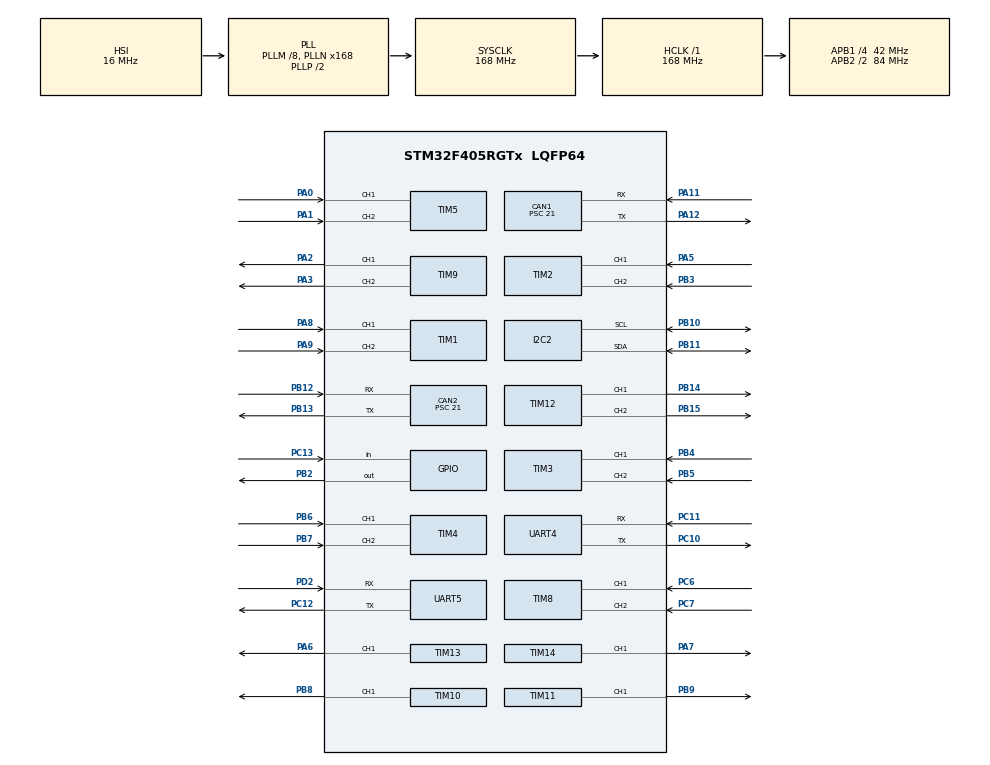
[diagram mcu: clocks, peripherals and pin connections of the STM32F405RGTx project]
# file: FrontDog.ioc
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CAN1.BS1=CAN_BS1_2TQ
CAN1.CalculateBaudRate=500000
CAN1.CalculateTimeBit=2000
CAN1.CalculateTimeQuantum=500.0
CAN1.NART=ENABLE
CAN1.Prescaler=21
CAN1.TXFP=ENABLE
CAN2.BS1=CAN_BS1_2TQ
CAN2.CalculateBaudRate=500000
CAN2.CalculateTimeBit=2000
CAN2.CalculateTimeQuantum=500.0
CAN2.NART=ENABLE
CAN2.Prescaler=21
CAN2.TXFP=ENABLE
Dma.Request0=UART4_RX
Dma.Request1=UART4_TX
Dma.Request2=UART5_RX
Dma.Request3=UART5_TX
Dma.UART4_RX.0.Direction=DMA_PERIPH_TO_MEMORY
Dma.UART4_RX.0.FIFOMode=DMA_FIFOMODE_DISABLE
Dma.UART4_RX.0.Instance=DMA1_Stream2
Dma.UART4_RX.0.MemDataAlignment=DMA_MDATAALIGN_BYTE
Dma.UART4_RX.0.MemInc=DMA_MINC_ENABLE
Dma.UART4_RX.0.Mode=DMA_NORMAL
Dma.UART4_RX.0.PeriphDataAlignment=DMA_PDATAALIGN_BYTE
Dma.UART4_RX.0.PeriphInc=DMA_PINC_DISABLE
Dma.UART4_RX.0.Priority=DMA_PRIORITY_LOW
Dma.UART4_TX.1.Direction=DMA_MEMORY_TO_PERIPH
Dma.UART4_TX.1.FIFOMode=DMA_FIFOMODE_DISABLE
Dma.UART4_TX.1.Instance=DMA1_Stream4
Dma.UART4_TX.1.MemDataAlignment=DMA_MDATAALIGN_BYTE
Dma.UART4_TX.1.MemInc=DMA_MINC_ENABLE
Dma.UART4_TX.1.Mode=DMA_NORMAL
Dma.UART4_TX.1.PeriphDataAlignment=DMA_PDATAALIGN_BYTE
Dma.UART4_TX.1.PeriphInc=DMA_PINC_DISABLE
Dma.UART4_TX.1.Priority=DMA_PRIORITY_LOW
Dma.UART5_RX.2.Direction=DMA_PERIPH_TO_MEMORY
Dma.UART5_RX.2.FIFOMode=DMA_FIFOMODE_DISABLE
Dma.UART5_RX.2.Instance=DMA1_Stream0
Dma.UART5_RX.2.MemDataAlignment=DMA_MDATAALIGN_BYTE
Dma.UART5_RX.2.MemInc=DMA_MINC_ENABLE
Dma.UART5_RX.2.Mode=DMA_NORMAL
Dma.UART5_RX.2.PeriphDataAlignment=DMA_PDATAALIGN_BYTE
Dma.UART5_RX.2.PeriphInc=DMA_PINC_DISABLE
Dma.UART5_RX.2.Priority=DMA_PRIORITY_LOW
Dma.UART5_TX.3.Direction=DMA_MEMORY_TO_PERIPH
Dma.UART5_TX.3.FIFOMode=DMA_FIFOMODE_DISABLE
Dma.UART5_TX.3.Instance=DMA1_Stream7
Dma.UART5_TX.3.MemDataAlignment=DMA_MDATAALIGN_BYTE
Dma.UART5_TX.3.MemInc=DMA_MINC_ENABLE
Dma.UART5_TX.3.Mode=DMA_NORMAL
Dma.UART5_TX.3.PeriphDataAlignment=DMA_PDATAALIGN_BYTE
Dma.UART5_TX.3.PeriphInc=DMA_PINC_DISABLE
Dma.UART5_TX.3.Priority=DMA_PRIORITY_LOW
FREERTOS.BinarySemaphores01=CAN_TX_BS,Static,CAN_TX_BSControlBlock,Available;UART_RX_BS,Static,UART_RX_BSControlBlock,Available
FREERTOS.CountingSemaphores01=UART_TX_CS,16,Static,UART_TX_CSControlBlock,0
FREERTOS.Queues01=UART_RX_Q,16,uint8_t,0,Static,UART_RX_QBuffer,UART_RX_QControlBlock;KEY_CMD_Q,16,App_Key_EventPacket_t,0,Static,KEY_CMD_QBuffer,KEY_CMD_QControlBlock;CAN_RXF0_Q,16,BSP_CAN_Packet_t,0,Static,CAN_RXF0_QBuffer,CAN_RXF0_QControlBlock;CAN_RXF1_Q,16,BSP_CAN_Packet_t,0,Static,CAN_RXF1_QBuffer,CAN_RXF1_QControlBlock;UART_TX_Q,16,APP_TxFrame_t,0,Static,UART_TX_QBuffer,UART_TX_QControlBlock
FREERTOS.Tasks01=KEY_Debounce_T,52,128,Task_KEY_Debounce,As weak,NULL,Static,KEY_Debounce_TBuffer,KEY_Debounce_TControlBlock;KEY_CMD_T,45,256,TASK_KEY_CMD,As weak,NULL,Static,KEY_CMD_TBuffer,KEY_CMD_TControlBlock;UART_RX_T,51,256,Task_UART_RX,As weak,NULL,Static,UART_RX_TBuffer,UART_RX_TControlBlock;UART_TX_T,38,128,Task_UART_TX,As weak,NULL,Static,UART_TX_TBuffer,UART_TX_TControlBlock;SERVO_T,46,64,Task_SERVO_T,As weak,NULL,Static,SERVO_TBuffer,SERVO_TControlBlock;OLED_T,14,128,Task_OLED,As weak,NULL,Static,OLED_TBuffer,OLED_TControlBlock;CAN_RXF0_T,54,256,Task_CAN_RXF0,As weak,NULL,Static,CAN_RXF0_TBuffer,CAN_RXF0_TControlBlock;CAN_RXF1_T,53,256,Task_CAN_RXF1,As weak,NULL,Static,CAN_RXF1_TBuffer,CAN_RXF1_TControlBlock;CAN_TX_T,37,64,Task_CAN_TX,As weak,NULL,Static,CAN_TX_TBuffer,CAN_TX_TControlBlock;UART_RX_CMD,50,128,Task_UART_RX_CMD,As weak,NULL,Static,UART_RX_CMDBuffer,UART_RX_CMDControlBlock
FREERTOS.configMINIMAL_STACK_SIZE=64
FREERTOS.configTOTAL_HEAP_SIZE=256
Mcu.Family=STM32F4
Mcu.Name=STM32F405RGTx
Mcu.Package=LQFP64
NVIC.CAN1_RX0_IRQn=true\:5\:0\:false\:false\:true\:true\:true\:true\:true
NVIC.CAN1_RX1_IRQn=true\:5\:0\:false\:false\:true\:true\:true\:true\:true
NVIC.CAN2_RX0_IRQn=true\:5\:0\:false\:false\:true\:true\:true\:true\:true
NVIC.CAN2_RX1_IRQn=true\:5\:0\:false\:false\:true\:true\:true\:true\:true
NVIC.DMA1_Stream0_IRQn=true\:5\:0\:false\:false\:true\:true\:false\:true\:true
NVIC.DMA1_Stream2_IRQn=true\:5\:0\:false\:false\:true\:true\:false\:true\:true
NVIC.DMA1_Stream4_IRQn=true\:5\:0\:false\:false\:true\:true\:false\:true\:true
NVIC.DMA1_Stream7_IRQn=true\:5\:0\:false\:false\:true\:true\:false\:true\:true
NVIC.PriorityGroup=NVIC_PRIORITYGROUP_4
NVIC.TIM6_DAC_IRQn=true\:15\:0\:false\:false\:true\:false\:false\:true\:true
NVIC.TimeBase=TIM6_DAC_IRQn
NVIC.TimeBaseIP=TIM6
NVIC.UART4_IRQn=true\:5\:0\:false\:false\:true\:true\:true\:true\:true
NVIC.UART5_IRQn=true\:5\:0\:false\:false\:true\:true\:true\:true\:true
PA0-WKUP.Signal=S_TIM5_CH1
PA1.Signal=S_TIM5_CH2
PA11.Mode=CAN_Activate
PA11.Signal=CAN1_RX
PA12.Mode=CAN_Activate
PA12.Signal=CAN1_TX
PA13.Mode=Serial_Wire
PA13.Signal=SYS_JTMS-SWDIO
PA14.Mode=Serial_Wire
PA14.Signal=SYS_JTCK-SWCLK
PA2.Signal=S_TIM9_CH1
PA3.Signal=S_TIM9_CH2
PA5.Signal=S_TIM2_CH1_ETR
PA6.Signal=S_TIM13_CH1
PA7.Signal=S_TIM14_CH1
PA8.Signal=S_TIM1_CH1
PA9.Signal=S_TIM1_CH2
PB10.Mode=I2C
PB10.Signal=I2C2_SCL
PB11.Mode=I2C
PB11.Signal=I2C2_SDA
PB12.Mode=CAN_Activate
PB12.Signal=CAN2_RX
PB13.Mode=CAN_Activate
PB13.Signal=CAN2_TX
PB14.Signal=S_TIM12_CH1
PB15.Signal=S_TIM12_CH2
PB2.GPIO_PuPd=GPIO_PULLDOWN
PB2.Signal=GPIO_Output
PB3.Signal=S_TIM2_CH2
PB4.Signal=S_TIM3_CH1
PB5.Signal=S_TIM3_CH2
PB6.Signal=S_TIM4_CH1
PB7.Signal=S_TIM4_CH2
PB8.Signal=S_TIM10_CH1
PB9.Signal=S_TIM11_CH1
PC10.Mode=Asynchronous
PC10.Signal=UART4_TX
PC11.Mode=Asynchronous
PC11.Signal=UART4_RX
PC12.Mode=Asynchronous
PC12.Signal=UART5_TX
PC13-ANTI_TAMP.GPIO_PuPd=GPIO_PULLDOWN
PC13-ANTI_TAMP.Signal=GPIO_Input
PC6.Signal=S_TIM8_CH1
PC7.Signal=S_TIM8_CH2
PD2.Mode=Asynchronous
PD2.Signal=UART5_RX
PH0-OSC_IN.Mode=HSE-External-Oscillator
PH0-OSC_IN.Signal=RCC_OSC_IN
PH1-OSC_OUT.Mode=HSE-External-Oscillator
PH1-OSC_OUT.Signal=RCC_OSC_OUT
ProjectManager.HeapSize=0x200
ProjectManager.StackSize=0x400
ProjectManager.TargetToolchain=CMake
RCC.48MHZClocksFreq_Value=84000000
RCC.AHBFreq_Value=168000000
RCC.APB1CLKDivider=RCC_HCLK_DIV4
RCC.APB1Freq_Value=42000000
RCC.APB1TimFreq_Value=84000000
RCC.APB2CLKDivider=RCC_HCLK_DIV2
RCC.APB2Freq_Value=84000000
RCC.APB2TimFreq_Value=168000000
RCC.CortexFreq_Value=168000000
RCC.HCLKFreq_Value=168000000
RCC.HSE_VALUE=8000000
RCC.HSI_VALUE=16000000
RCC.LSE_VALUE=32768
RCC.PLLM=8
RCC.PLLN=168
RCC.SYSCLKFreq_VALUE=168000000
RCC.SYSCLKSource=RCC_SYSCLKSOURCE_PLLCLK
RCC.VCOOutputFreq_Value=336000000
SH.S_TIM10_CH1.0=TIM10_CH1,PWM Generation1 CH1
SH.S_TIM11_CH1.0=TIM11_CH1,PWM Generation1 CH1
SH.S_TIM12_CH1.0=TIM12_CH1,PWM Generation1 CH1
SH.S_TIM12_CH2.0=TIM12_CH2,PWM Generation2 CH2
SH.S_TIM13_CH1.0=TIM13_CH1,PWM Generation1 CH1
SH.S_TIM14_CH1.0=TIM14_CH1,PWM Generation1 CH1
SH.S_TIM1_CH1.0=TIM1_CH1,Encoder_Interface
SH.S_TIM1_CH2.0=TIM1_CH2,Encoder_Interface
SH.S_TIM2_CH1_ETR.0=TIM2_CH1,Encoder_Interface
SH.S_TIM2_CH2.0=TIM2_CH2,Encoder_Interface
SH.S_TIM3_CH1.0=TIM3_CH1,Encoder_Interface
SH.S_TIM3_CH2.0=TIM3_CH2,Encoder_Interface
SH.S_TIM4_CH1.0=TIM4_CH1,Encoder_Interface
SH.S_TIM4_CH2.0=TIM4_CH2,Encoder_Interface
SH.S_TIM5_CH1.0=TIM5_CH1,Encoder_Interface
SH.S_TIM5_CH2.0=TIM5_CH2,Encoder_Interface
SH.S_TIM8_CH1.0=TIM8_CH1,Encoder_Interface
SH.S_TIM8_CH2.0=TIM8_CH2,Encoder_Interface
SH.S_TIM9_CH1.0=TIM9_CH1,PWM Generation1 CH1
SH.S_TIM9_CH2.0=TIM9_CH2,PWM Generation2 CH2
TIM10.Channel=TIM_CHANNEL_1
TIM11.Channel=TIM_CHANNEL_1
TIM12.Channel-PWM\ Generation1\ CH1=TIM_CHANNEL_1
TIM12.Channel-PWM\ Generation2\ CH2=TIM_CHANNEL_2
TIM13.Channel=TIM_CHANNEL_1
TIM14.Channel=TIM_CHANNEL_1
TIM9.Channel-PWM\ Generation1\ CH1=TIM_CHANNEL_1
TIM9.Channel-PWM\ Generation2\ CH2=TIM_CHANNEL_2
UART4.VirtualMode=Asynchronous
UART5.VirtualMode=Asynchronous
VP_FREERTOS_VS_CMSIS_V2.Mode=CMSIS_V2
VP_SYS_VS_tim6.Mode=TIM6
VP_TIM10_VS_ClockSourceINT.Mode=Enable_Timer
VP_TIM11_VS_ClockSourceINT.Mode=Enable_Timer
VP_TIM12_VS_ClockSourceINT.Mode=Internal
VP_TIM13_VS_ClockSourceINT.Mode=Enable_Timer
VP_TIM14_VS_ClockSourceINT.Mode=Enable_Timer
VP_TIM9_VS_ClockSourceINT.Mode=Internal
board=custom

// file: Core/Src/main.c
/* USER CODE BEGIN Header */
/**
  ******************************************************************************
  * @file           : main.c
  * @brief          : Main program body
  ******************************************************************************
  * @attention
  *
  * Copyright (c) 2026 STMicroelectronics.
  * All rights reserved.
  *
  * This software is licensed under terms that can be found in the LICENSE file
  * in the root directory of this software component.
  * If no LICENSE file comes with this software, it is provided AS-IS.
  *
  ******************************************************************************
  */
/* USER CODE END Header */
#include "main.h"
#include "cmsis_os.h"
#include "can.h"
#include "dma.h"
#include "i2c.h"
#include "tim.h"
#include "usart.h"
#include "gpio.h"

void SystemClock_Config(void);
void MX_FREERTOS_Init(void);

int main(void)
{

  /* MCU Configuration--------------------------------------------------------*/

  /* Reset of all peripherals, Initializes the Flash interface and the Systick. */
  HAL_Init();

  /* Configure the system clock */
  SystemClock_Config();

  /* Initialize all configured peripherals */
  MX_GPIO_Init();
  MX_DMA_Init();
  MX_CAN1_Init();
  MX_CAN2_Init();
  MX_I2C2_Init();
  MX_TIM1_Init();
  MX_TIM2_Init();
  MX_TIM3_Init();
  MX_TIM4_Init();
  MX_TIM5_Init();
  MX_TIM8_Init();
  MX_TIM9_Init();
  MX_TIM10_Init();
  MX_TIM11_Init();
  MX_TIM12_Init();
  MX_TIM13_Init();
  MX_TIM14_Init();
  MX_UART4_Init();
  MX_UART5_Init();

  /* Init scheduler */
  osKernelInitialize();  /* Call init function for freertos objects (in cmsis_os2.c) */
  MX_FREERTOS_Init();

  /* Start scheduler */
  osKernelStart();

  /* We should never get here as control is now taken by the scheduler */

  /* Infinite loop */
  while (1)
  {

  }
}

void SystemClock_Config(void)
{
  RCC_OscInitTypeDef RCC_OscInitStruct = {0};
  RCC_ClkInitTypeDef RCC_ClkInitStruct = {0};

  /** Configure the main internal regulator output voltage
  */
  __HAL_RCC_PWR_CLK_ENABLE();
  __HAL_PWR_VOLTAGESCALING_CONFIG(PWR_REGULATOR_VOLTAGE_SCALE1);

  /** Initializes the RCC Oscillators according to the specified parameters
  * in the RCC_OscInitTypeDef structure.
  */
  RCC_OscInitStruct.OscillatorType = RCC_OSCILLATORTYPE_HSI;
  RCC_OscInitStruct.HSIState = RCC_HSI_ON;
  RCC_OscInitStruct.HSICalibrationValue = RCC_HSICALIBRATION_DEFAULT;
  RCC_OscInitStruct.PLL.PLLState = RCC_PLL_ON;
  RCC_OscInitStruct.PLL.PLLSource = RCC_PLLSOURCE_HSI;
  RCC_OscInitStruct.PLL.PLLM = 8;
  RCC_OscInitStruct.PLL.PLLN = 168;
  RCC_OscInitStruct.PLL.PLLP = RCC_PLLP_DIV2;
  RCC_OscInitStruct.PLL.PLLQ = 4;
  if (HAL_RCC_OscConfig(&RCC_OscInitStruct) != HAL_OK)
  {
    Error_Handler();
  }

  /** Initializes the CPU, AHB and APB buses clocks
  */
  RCC_ClkInitStruct.ClockType = RCC_CLOCKTYPE_HCLK|RCC_CLOCKTYPE_SYSCLK
                              |RCC_CLOCKTYPE_PCLK1|RCC_CLOCKTYPE_PCLK2;
  RCC_ClkInitStruct.SYSCLKSource = RCC_SYSCLKSOURCE_PLLCLK;
  RCC_ClkInitStruct.AHBCLKDivider = RCC_SYSCLK_DIV1;
  RCC_ClkInitStruct.APB1CLKDivider = RCC_HCLK_DIV4;
  RCC_ClkInitStruct.APB2CLKDivider = RCC_HCLK_DIV2;

  if (HAL_RCC_ClockConfig(&RCC_ClkInitStruct, FLASH_LATENCY_5) != HAL_OK)
  {
    Error_Handler();
  }
}

void HAL_TIM_PeriodElapsedCallback(TIM_HandleTypeDef *htim)
{
  if (htim->Instance == TIM6)
  {
    HAL_IncTick();
  }
}

void Error_Handler(void)
{
  __disable_irq();
  while (1)
  {
  }
}

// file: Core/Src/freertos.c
/* USER CODE BEGIN Header */
/**
  ******************************************************************************
  * File Name          : freertos.c
  * Description        : Code for freertos applications
  ******************************************************************************
  * @attention
  *
  * Copyright (c) 2026 STMicroelectronics.
  * All rights reserved.
  *
  * This software is licensed under terms that can be found in the LICENSE file
  * in the root directory of this software component.
  * If no LICENSE file comes with this software, it is provided AS-IS.
  *
  ******************************************************************************
  */
/* USER CODE END Header */

#include "FreeRTOS.h"
#include "task.h"
#include "main.h"
#include "cmsis_os.h"

/* USER CODE BEGIN Includes */
#include "app_key.h"
#include "bsp_can.h"
#include "app_uart.h"
/* USER CODE END Includes */

typedef StaticTask_t osStaticThreadDef_t;
typedef StaticQueue_t osStaticMessageQDef_t;
typedef StaticSemaphore_t osStaticSemaphoreDef_t;

/* Definitions for KEY_Debounce_T */
osThreadId_t KEY_Debounce_THandle;
uint32_t KEY_Debounce_TBuffer[ 128 ];
osStaticThreadDef_t KEY_Debounce_TControlBlock;
const osThreadAttr_t KEY_Debounce_T_attributes = {
  .name = "KEY_Debounce_T",
  .cb_mem = &KEY_Debounce_TControlBlock,
  .cb_size = sizeof(KEY_Debounce_TControlBlock),
  .stack_mem = &KEY_Debounce_TBuffer[0],
  .stack_size = sizeof(KEY_Debounce_TBuffer),
  .priority = (osPriority_t) osPriorityRealtime4,
};
/* Definitions for KEY_CMD_T */
osThreadId_t KEY_CMD_THandle;
uint32_t KEY_CMD_TBuffer[ 256 ];
osStaticThreadDef_t KEY_CMD_TControlBlock;
const osThreadAttr_t KEY_CMD_T_attributes = {
  .name = "KEY_CMD_T",
  .cb_mem = &KEY_CMD_TControlBlock,
  .cb_size = sizeof(KEY_CMD_TControlBlock),
  .stack_mem = &KEY_CMD_TBuffer[0],
  .stack_size = sizeof(KEY_CMD_TBuffer),
  .priority = (osPriority_t) osPriorityHigh5,
};
/* Definitions for UART_RX_T */
osThreadId_t UART_RX_THandle;
uint32_t UART_RX_TBuffer[ 256 ];
osStaticThreadDef_t UART_RX_TControlBlock;
const osThreadAttr_t UART_RX_T_attributes = {
  .name = "UART_RX_T",
  .cb_mem = &UART_RX_TControlBlock,
  .cb_size = sizeof(UART_RX_TControlBlock),
  .stack_mem = &UART_RX_TBuffer[0],
  .stack_size = sizeof(UART_RX_TBuffer),
  .priority = (osPriority_t) osPriorityRealtime3,
};
/* Definitions for UART_TX_T */
osThreadId_t UART_TX_THandle;
uint32_t UART_TX_TBuffer[ 128 ];
osStaticThreadDef_t UART_TX_TControlBlock;
const osThreadAttr_t UART_TX_T_attributes = {
  .name = "UART_TX_T",
  .cb_mem = &UART_TX_TControlBlock,
  .cb_size = sizeof(UART_TX_TControlBlock),
  .stack_mem = &UART_TX_TBuffer[0],
  .stack_size = sizeof(UART_TX_TBuffer),
  .priority = (osPriority_t) osPriorityAboveNormal6,
};
/* Definitions for SERVO_T */
osThreadId_t SERVO_THandle;
uint32_t SERVO_TBuffer[ 64 ];
osStaticThreadDef_t SERVO_TControlBlock;
const osThreadAttr_t SERVO_T_attributes = {
  .name = "SERVO_T",
  .cb_mem = &SERVO_TControlBlock,
  .cb_size = sizeof(SERVO_TControlBlock),
  .stack_mem = &SERVO_TBuffer[0],
  .stack_size = sizeof(SERVO_TBuffer),
  .priority = (osPriority_t) osPriorityHigh6,
};
/* Definitions for OLED_T */
osThreadId_t OLED_THandle;
uint32_t OLED_TBuffer[ 128 ];
osStaticThreadDef_t OLED_TControlBlock;
const osThreadAttr_t OLED_T_attributes = {
  .name = "OLED_T",
  .cb_mem = &OLED_TControlBlock,
  .cb_size = sizeof(OLED_TControlBlock),
  .stack_mem = &OLED_TBuffer[0],
  .stack_size = sizeof(OLED_TBuffer),
  .priority = (osPriority_t) osPriorityLow6,
};
/* Definitions for CAN_RXF0_T */
osThreadId_t CAN_RXF0_THandle;
uint32_t CAN_RXF0_TBuffer[ 256 ];
osStaticThreadDef_t CAN_RXF0_TControlBlock;
const osThreadAttr_t CAN_RXF0_T_attributes = {
  .name = "CAN_RXF0_T",
  .cb_mem = &CAN_RXF0_TControlBlock,
  .cb_size = sizeof(CAN_RXF0_TControlBlock),
  .stack_mem = &CAN_RXF0_TBuffer[0],
  .stack_size = sizeof(CAN_RXF0_TBuffer),
  .priority = (osPriority_t) osPriorityRealtime6,
};
/* Definitions for CAN_RXF1_T */
osThreadId_t CAN_RXF1_THandle;
uint32_t CAN_RXF1_TBuffer[ 256 ];
osStaticThreadDef_t CAN_RXF1_TControlBlock;
const osThreadAttr_t CAN_RXF1_T_attributes = {
  .name = "CAN_RXF1_T",
  .cb_mem = &CAN_RXF1_TControlBlock,
  .cb_size = sizeof(CAN_RXF1_TControlBlock),
  .stack_mem = &CAN_RXF1_TBuffer[0],
  .stack_size = sizeof(CAN_RXF1_TBuffer),
  .priority = (osPriority_t) osPriorityRealtime5,
};
/* Definitions for CAN_TX_T */
osThreadId_t CAN_TX_THandle;
uint32_t CAN_TX_TBuffer[ 64 ];
osStaticThreadDef_t CAN_TX_TControlBlock;
const osThreadAttr_t CAN_TX_T_attributes = {
  .name = "CAN_TX_T",
  .cb_mem = &CAN_TX_TControlBlock,
  .cb_size = sizeof(CAN_TX_TControlBlock),
  .stack_mem = &CAN_TX_TBuffer[0],
  .stack_size = sizeof(CAN_TX_TBuffer),
  .priority = (osPriority_t) osPriorityAboveNormal5,
};
/* Definitions for UART_RX_CMD */
osThreadId_t UART_RX_CMDHandle;
uint32_t UART_RX_CMDBuffer[ 128 ];
osStaticThreadDef_t UART_RX_CMDControlBlock;
const osThreadAttr_t UART_RX_CMD_attributes = {
  .name = "UART_RX_CMD",
  .cb_mem = &UART_RX_CMDControlBlock,
  .cb_size = sizeof(UART_RX_CMDControlBlock),
  .stack_mem = &UART_RX_CMDBuffer[0],
  .stack_size = sizeof(UART_RX_CMDBuffer),
  .priority = (osPriority_t) osPriorityRealtime2,
};
/* Definitions for UART_RX_Q */
osMessageQueueId_t UART_RX_QHandle;
uint8_t UART_RX_QBuffer[ 16 * sizeof( uint8_t ) ];
osStaticMessageQDef_t UART_RX_QControlBlock;
const osMessageQueueAttr_t UART_RX_Q_attributes = {
  .name = "UART_RX_Q",
  .cb_mem = &UART_RX_QControlBlock,
  .cb_size = sizeof(UART_RX_QControlBlock),
  .mq_mem = &UART_RX_QBuffer,
  .mq_size = sizeof(UART_RX_QBuffer)
};
/* Definitions for KEY_CMD_Q */
osMessageQueueId_t KEY_CMD_QHandle;
uint8_t KEY_CMD_QBuffer[ 16 * sizeof( App_Key_EventPacket_t ) ];
osStaticMessageQDef_t KEY_CMD_QControlBlock;
const osMessageQueueAttr_t KEY_CMD_Q_attributes = {
  .name = "KEY_CMD_Q",
  .cb_mem = &KEY_CMD_QControlBlock,
  .cb_size = sizeof(KEY_CMD_QControlBlock),
  .mq_mem = &KEY_CMD_QBuffer,
  .mq_size = sizeof(KEY_CMD_QBuffer)
};
/* Definitions for CAN_RXF0_Q */
osMessageQueueId_t CAN_RXF0_QHandle;
uint8_t CAN_RXF0_QBuffer[ 16 * sizeof( BSP_CAN_Packet_t ) ];
osStaticMessageQDef_t CAN_RXF0_QControlBlock;
const osMessageQueueAttr_t CAN_RXF0_Q_attributes = {
  .name = "CAN_RXF0_Q",
  .cb_mem = &CAN_RXF0_QControlBlock,
  .cb_size = sizeof(CAN_RXF0_QControlBlock),
  .mq_mem = &CAN_RXF0_QBuffer,
  .mq_size = sizeof(CAN_RXF0_QBuffer)
};
/* Definitions for CAN_RXF1_Q */
osMessageQueueId_t CAN_RXF1_QHandle;
uint8_t CAN_RXF1_QBuffer[ 16 * sizeof( BSP_CAN_Packet_t ) ];
osStaticMessageQDef_t CAN_RXF1_QControlBlock;
const osMessageQueueAttr_t CAN_RXF1_Q_attributes = {
  .name = "CAN_RXF1_Q",
  .cb_mem = &CAN_RXF1_QControlBlock,
  .cb_size = sizeof(CAN_RXF1_QControlBlock),
  .mq_mem = &CAN_RXF1_QBuffer,
  .mq_size = sizeof(CAN_RXF1_QBuffer)
};
/* Definitions for UART_TX_Q */
osMessageQueueId_t UART_TX_QHandle;
uint8_t UART_TX_QBuffer[ 16 * sizeof( APP_TxFrame_t ) ];
osStaticMessageQDef_t UART_TX_QControlBlock;
const osMessageQueueAttr_t UART_TX_Q_attributes = {
  .name = "UART_TX_Q",
  .cb_mem = &UART_TX_QControlBlock,
  .cb_size = sizeof(UART_TX_QControlBlock),
  .mq_mem = &UART_TX_QBuffer,
  .mq_size = sizeof(UART_TX_QBuffer)
};
/* Definitions for CAN_TX_BS */
osSemaphoreId_t CAN_TX_BSHandle;
osStaticSemaphoreDef_t CAN_TX_BSControlBlock;
const osSemaphoreAttr_t CAN_TX_BS_attributes = {
  .name = "CAN_TX_BS",
  .cb_mem = &CAN_TX_BSControlBlock,
  .cb_size = sizeof(CAN_TX_BSControlBlock),
};
/* Definitions for UART_RX_BS */
osSemaphoreId_t UART_RX_BSHandle;
osStaticSemaphoreDef_t UART_RX_BSControlBlock;
const osSemaphoreAttr_t UART_RX_BS_attributes = {
  .name = "UART_RX_BS",
  .cb_mem = &UART_RX_BSControlBlock,
  .cb_size = sizeof(UART_RX_BSControlBlock),
};
/* Definitions for UART_TX_CS */
osSemaphoreId_t UART_TX_CSHandle;
osStaticSemaphoreDef_t UART_TX_CSControlBlock;
const osSemaphoreAttr_t UART_TX_CS_attributes = {
  .name = "UART_TX_CS",
  .cb_mem = &UART_TX_CSControlBlock,
  .cb_size = sizeof(UART_TX_CSControlBlock),
};

void Task_KEY_Debounce(void *argument);
void TASK_KEY_CMD(void *argument);
void Task_UART_RX(void *argument);
void Task_UART_TX(void *argument);
void Task_SERVO_T(void *argument);
void Task_OLED(void *argument);
void Task_CAN_RXF0(void *argument);
void Task_CAN_RXF1(void *argument);
void Task_CAN_TX(void *argument);
void Task_UART_RX_CMD(void *argument);

void MX_FREERTOS_Init(void); /* (MISRA C 2004 rule 8.1) */

void MX_FREERTOS_Init(void) {

  /* Create the semaphores(s) */
  /* creation of CAN_TX_BS */
  CAN_TX_BSHandle = osSemaphoreNew(1, 1, &CAN_TX_BS_attributes);

  /* creation of UART_RX_BS */
  UART_RX_BSHandle = osSemaphoreNew(1, 1, &UART_RX_BS_attributes);

  /* creation of UART_TX_CS */
  UART_TX_CSHandle = osSemaphoreNew(16, 0, &UART_TX_CS_attributes);

  /* Create the queue(s) */
  /* creation of UART_RX_Q */
  UART_RX_QHandle = osMessageQueueNew (16, sizeof(uint8_t), &UART_RX_Q_attributes);

  /* creation of KEY_CMD_Q */
  KEY_CMD_QHandle = osMessageQueueNew (16, sizeof(App_Key_EventPacket_t), &KEY_CMD_Q_attributes);

  /* creation of CAN_RXF0_Q */
  CAN_RXF0_QHandle = osMessageQueueNew (16, sizeof(BSP_CAN_Packet_t), &CAN_RXF0_Q_attributes);

  /* creation of CAN_RXF1_Q */
  CAN_RXF1_QHandle = osMessageQueueNew (16, sizeof(BSP_CAN_Packet_t), &CAN_RXF1_Q_attributes);

  /* creation of UART_TX_Q */
  UART_TX_QHandle = osMessageQueueNew (16, sizeof(APP_TxFrame_t), &UART_TX_Q_attributes);

  /* Create the thread(s) */
  /* creation of KEY_Debounce_T */
  KEY_Debounce_THandle = osThreadNew(Task_KEY_Debounce, NULL, &KEY_Debounce_T_attributes);

  /* creation of KEY_CMD_T */
  KEY_CMD_THandle = osThreadNew(TASK_KEY_CMD, NULL, &KEY_CMD_T_attributes);

  /* creation of UART_RX_T */
  UART_RX_THandle = osThreadNew(Task_UART_RX, NULL, &UART_RX_T_attributes);

  /* creation of UART_TX_T */
  UART_TX_THandle = osThreadNew(Task_UART_TX, NULL, &UART_TX_T_attributes);

  /* creation of SERVO_T */
  SERVO_THandle = osThreadNew(Task_SERVO_T, NULL, &SERVO_T_attributes);

  /* creation of OLED_T */
  OLED_THandle = osThreadNew(Task_OLED, NULL, &OLED_T_attributes);

  /* creation of CAN_RXF0_T */
  CAN_RXF0_THandle = osThreadNew(Task_CAN_RXF0, NULL, &CAN_RXF0_T_attributes);

  /* creation of CAN_RXF1_T */
  CAN_RXF1_THandle = osThreadNew(Task_CAN_RXF1, NULL, &CAN_RXF1_T_attributes);

  /* creation of CAN_TX_T */
  CAN_TX_THandle = osThreadNew(Task_CAN_TX, NULL, &CAN_TX_T_attributes);

  /* creation of UART_RX_CMD */
  UART_RX_CMDHandle = osThreadNew(Task_UART_RX_CMD, NULL, &UART_RX_CMD_attributes);

}

__weak void Task_KEY_Debounce(void *argument)
{
  for(;;)
  {
    osDelay(1);
  }
}

__weak void TASK_KEY_CMD(void *argument)
{
  for(;;)
  {
    osDelay(1);
  }
}

__weak void Task_UART_RX(void *argument)
{
  for(;;)
  {
    osDelay(1);
  }
}

__weak void Task_UART_TX(void *argument)
{
  for(;;)
  {
    osDelay(1);
  }
}

__weak void Task_SERVO_T(void *argument)
{
  for(;;)
  {
    osDelay(1);
  }
}

__weak void Task_OLED(void *argument)
{
  for(;;)
  {
    osDelay(1);
  }
}

__weak void Task_CAN_RXF0(void *argument)
{
  for(;;)
  {
    osDelay(1);
  }
}

__weak void Task_CAN_RXF1(void *argument)
{
  for(;;)
  {
    osDelay(1);
  }
}

__weak void Task_CAN_TX(void *argument)
{
  for(;;)
  {
    osDelay(1);
  }
}

__weak void Task_UART_RX_CMD(void *argument)
{
  for(;;)
  {
    osDelay(1);
  }
}
